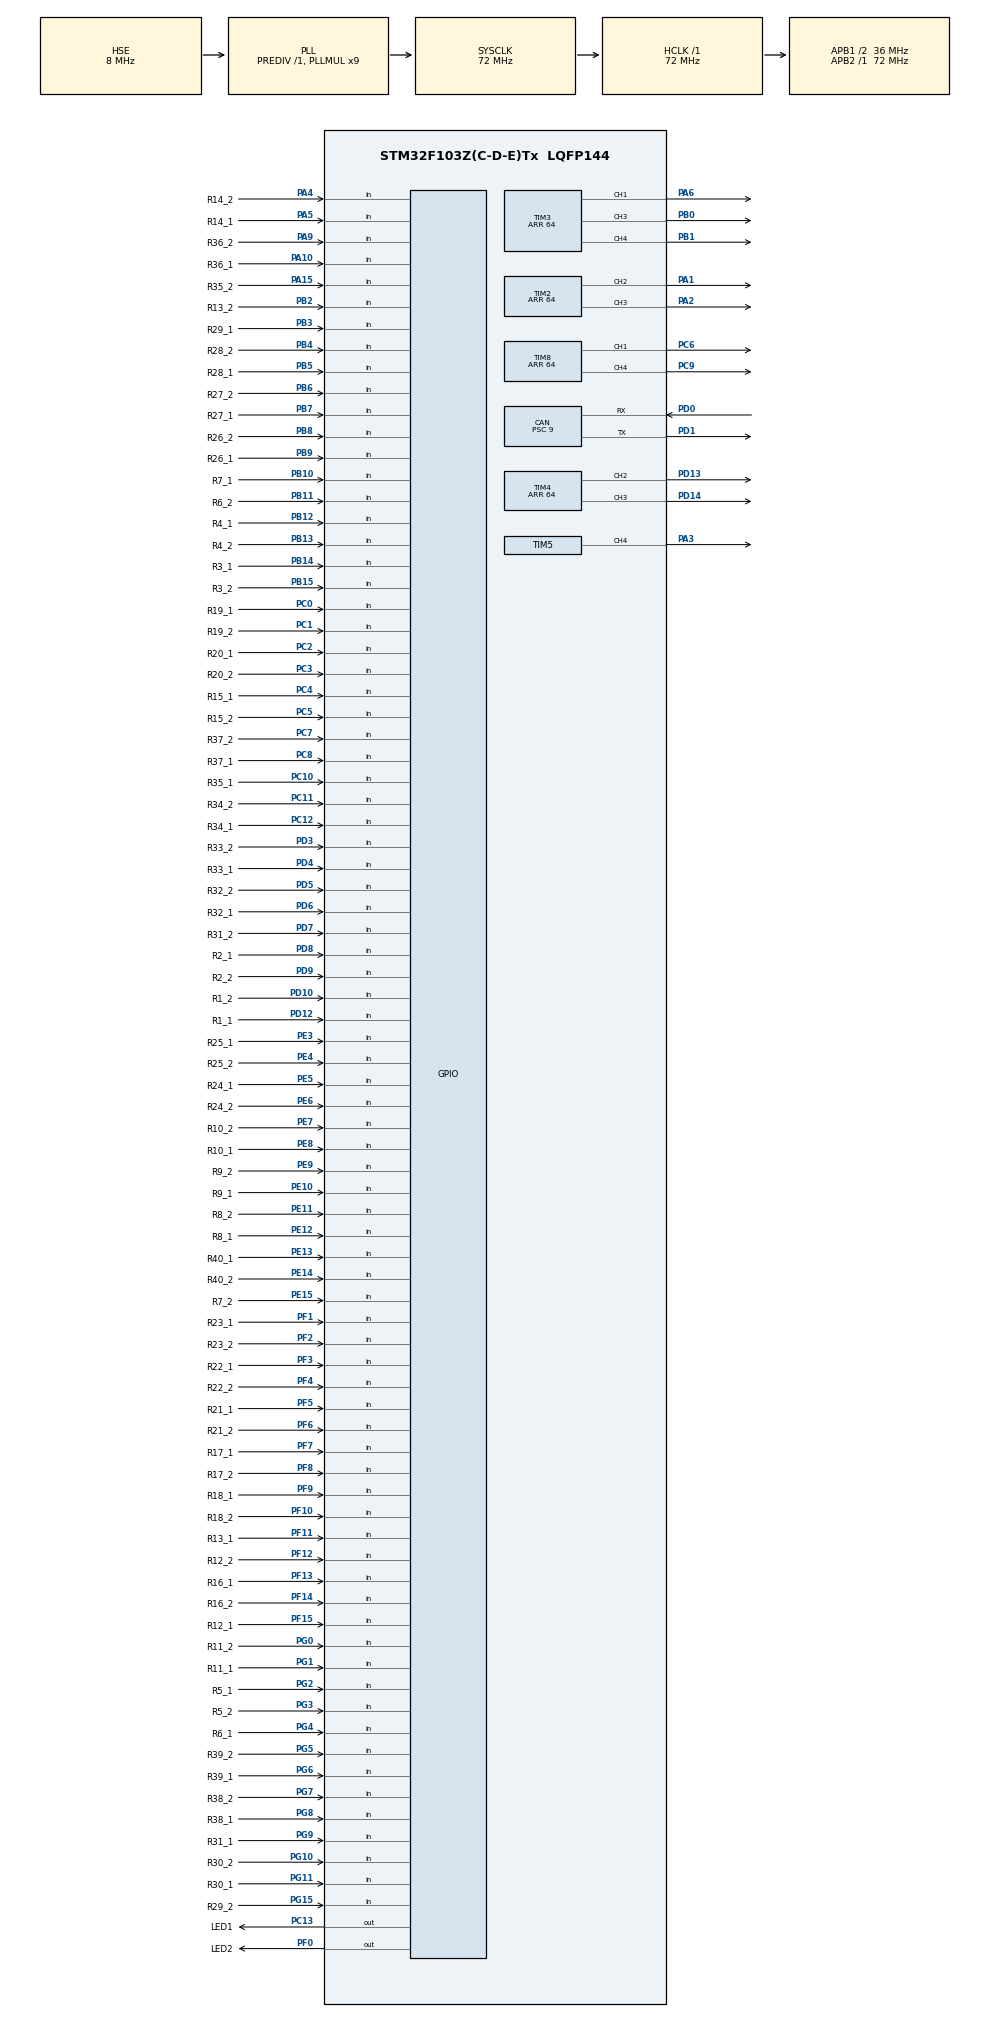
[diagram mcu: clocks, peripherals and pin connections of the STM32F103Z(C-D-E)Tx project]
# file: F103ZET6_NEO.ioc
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CAN.BS1=CAN_BS1_3TQ
CAN.BS2=CAN_BS2_4TQ
CAN.CalculateBaudRate=500000
CAN.CalculateTimeBit=2000
CAN.CalculateTimeQuantum=250.0
CAN.Prescaler=9
CAN.SJW=CAN_SJW_1TQ
Dma.Request0=TIM4_CH2
Dma.Request1=TIM4_CH3
Dma.Request2=TIM2_CH3
Dma.Request3=TIM2_CH2/CH4
Dma.Request4=TIM3_CH1/TRIG
Dma.Request5=TIM3_CH3
Dma.Request6=TIM3_CH4/UP
Dma.Request7=TIM5_CH4/TRIG
Dma.Request8=TIM8_CH4/TRIG/COM
Dma.Request9=TIM8_CH1
Dma.TIM2_CH2/CH4.3.Direction=DMA_MEMORY_TO_PERIPH
Dma.TIM2_CH2/CH4.3.Instance=DMA1_Channel7
Dma.TIM2_CH2/CH4.3.MemDataAlignment=DMA_MDATAALIGN_WORD
Dma.TIM2_CH2/CH4.3.MemInc=DMA_MINC_ENABLE
Dma.TIM2_CH2/CH4.3.Mode=DMA_NORMAL
Dma.TIM2_CH2/CH4.3.PeriphDataAlignment=DMA_PDATAALIGN_WORD
Dma.TIM2_CH2/CH4.3.PeriphInc=DMA_PINC_DISABLE
Dma.TIM2_CH2/CH4.3.Priority=DMA_PRIORITY_VERY_HIGH
Dma.TIM2_CH3.2.Direction=DMA_MEMORY_TO_PERIPH
Dma.TIM2_CH3.2.Instance=DMA1_Channel1
Dma.TIM2_CH3.2.MemDataAlignment=DMA_MDATAALIGN_WORD
Dma.TIM2_CH3.2.MemInc=DMA_MINC_ENABLE
Dma.TIM2_CH3.2.Mode=DMA_NORMAL
Dma.TIM2_CH3.2.PeriphDataAlignment=DMA_PDATAALIGN_WORD
Dma.TIM2_CH3.2.PeriphInc=DMA_PINC_DISABLE
Dma.TIM2_CH3.2.Priority=DMA_PRIORITY_VERY_HIGH
Dma.TIM3_CH1/TRIG.4.Direction=DMA_MEMORY_TO_PERIPH
Dma.TIM3_CH1/TRIG.4.Instance=DMA1_Channel6
Dma.TIM3_CH1/TRIG.4.MemDataAlignment=DMA_MDATAALIGN_WORD
Dma.TIM3_CH1/TRIG.4.MemInc=DMA_MINC_ENABLE
Dma.TIM3_CH1/TRIG.4.Mode=DMA_NORMAL
Dma.TIM3_CH1/TRIG.4.PeriphDataAlignment=DMA_PDATAALIGN_WORD
Dma.TIM3_CH1/TRIG.4.PeriphInc=DMA_PINC_DISABLE
Dma.TIM3_CH1/TRIG.4.Priority=DMA_PRIORITY_VERY_HIGH
Dma.TIM3_CH3.5.Direction=DMA_MEMORY_TO_PERIPH
Dma.TIM3_CH3.5.Instance=DMA1_Channel2
Dma.TIM3_CH3.5.MemDataAlignment=DMA_MDATAALIGN_WORD
Dma.TIM3_CH3.5.MemInc=DMA_MINC_ENABLE
Dma.TIM3_CH3.5.Mode=DMA_NORMAL
Dma.TIM3_CH3.5.PeriphDataAlignment=DMA_PDATAALIGN_WORD
Dma.TIM3_CH3.5.PeriphInc=DMA_PINC_DISABLE
Dma.TIM3_CH3.5.Priority=DMA_PRIORITY_VERY_HIGH
Dma.TIM3_CH4/UP.6.Direction=DMA_MEMORY_TO_PERIPH
Dma.TIM3_CH4/UP.6.Instance=DMA1_Channel3
Dma.TIM3_CH4/UP.6.MemDataAlignment=DMA_MDATAALIGN_WORD
Dma.TIM3_CH4/UP.6.MemInc=DMA_MINC_ENABLE
Dma.TIM3_CH4/UP.6.Mode=DMA_NORMAL
Dma.TIM3_CH4/UP.6.PeriphDataAlignment=DMA_PDATAALIGN_WORD
Dma.TIM3_CH4/UP.6.PeriphInc=DMA_PINC_DISABLE
Dma.TIM3_CH4/UP.6.Priority=DMA_PRIORITY_VERY_HIGH
Dma.TIM4_CH2.0.Direction=DMA_MEMORY_TO_PERIPH
Dma.TIM4_CH2.0.Instance=DMA1_Channel4
Dma.TIM4_CH2.0.MemDataAlignment=DMA_MDATAALIGN_WORD
Dma.TIM4_CH2.0.MemInc=DMA_MINC_ENABLE
Dma.TIM4_CH2.0.Mode=DMA_NORMAL
Dma.TIM4_CH2.0.PeriphDataAlignment=DMA_PDATAALIGN_WORD
Dma.TIM4_CH2.0.PeriphInc=DMA_PINC_DISABLE
Dma.TIM4_CH2.0.Priority=DMA_PRIORITY_VERY_HIGH
Dma.TIM4_CH3.1.Direction=DMA_MEMORY_TO_PERIPH
Dma.TIM4_CH3.1.Instance=DMA1_Channel5
Dma.TIM4_CH3.1.MemDataAlignment=DMA_MDATAALIGN_WORD
Dma.TIM4_CH3.1.MemInc=DMA_MINC_ENABLE
Dma.TIM4_CH3.1.Mode=DMA_NORMAL
Dma.TIM4_CH3.1.PeriphDataAlignment=DMA_PDATAALIGN_WORD
Dma.TIM4_CH3.1.PeriphInc=DMA_PINC_DISABLE
Dma.TIM4_CH3.1.Priority=DMA_PRIORITY_VERY_HIGH
Dma.TIM5_CH4/TRIG.7.Direction=DMA_MEMORY_TO_PERIPH
Dma.TIM5_CH4/TRIG.7.Instance=DMA2_Channel1
Dma.TIM5_CH4/TRIG.7.MemDataAlignment=DMA_MDATAALIGN_WORD
Dma.TIM5_CH4/TRIG.7.MemInc=DMA_MINC_ENABLE
Dma.TIM5_CH4/TRIG.7.Mode=DMA_NORMAL
Dma.TIM5_CH4/TRIG.7.PeriphDataAlignment=DMA_PDATAALIGN_WORD
Dma.TIM5_CH4/TRIG.7.PeriphInc=DMA_PINC_DISABLE
Dma.TIM5_CH4/TRIG.7.Priority=DMA_PRIORITY_VERY_HIGH
Dma.TIM8_CH1.9.Direction=DMA_MEMORY_TO_PERIPH
Dma.TIM8_CH1.9.Instance=DMA2_Channel3
Dma.TIM8_CH1.9.MemDataAlignment=DMA_MDATAALIGN_WORD
Dma.TIM8_CH1.9.MemInc=DMA_MINC_ENABLE
Dma.TIM8_CH1.9.Mode=DMA_NORMAL
Dma.TIM8_CH1.9.PeriphDataAlignment=DMA_PDATAALIGN_WORD
Dma.TIM8_CH1.9.PeriphInc=DMA_PINC_DISABLE
Dma.TIM8_CH1.9.Priority=DMA_PRIORITY_VERY_HIGH
Dma.TIM8_CH4/TRIG/COM.8.Direction=DMA_MEMORY_TO_PERIPH
Dma.TIM8_CH4/TRIG/COM.8.Instance=DMA2_Channel2
Dma.TIM8_CH4/TRIG/COM.8.MemDataAlignment=DMA_MDATAALIGN_WORD
Dma.TIM8_CH4/TRIG/COM.8.MemInc=DMA_MINC_ENABLE
Dma.TIM8_CH4/TRIG/COM.8.Mode=DMA_NORMAL
Dma.TIM8_CH4/TRIG/COM.8.PeriphDataAlignment=DMA_PDATAALIGN_WORD
Dma.TIM8_CH4/TRIG/COM.8.PeriphInc=DMA_PINC_DISABLE
Dma.TIM8_CH4/TRIG/COM.8.Priority=DMA_PRIORITY_VERY_HIGH
Mcu.Family=STM32F1
Mcu.Name=STM32F103Z(C-D-E)Tx
Mcu.Package=LQFP144
NVIC.DMA1_Channel1_IRQn=true\:0\:0\:false\:false\:true\:false\:true\:true
NVIC.DMA1_Channel2_IRQn=true\:0\:0\:false\:false\:true\:false\:true\:true
NVIC.DMA1_Channel3_IRQn=true\:0\:0\:false\:false\:true\:false\:true\:true
NVIC.DMA1_Channel4_IRQn=true\:0\:0\:false\:false\:true\:false\:true\:true
NVIC.DMA1_Channel5_IRQn=true\:0\:0\:false\:false\:true\:false\:true\:true
NVIC.DMA1_Channel6_IRQn=true\:0\:0\:false\:false\:true\:false\:true\:true
NVIC.DMA1_Channel7_IRQn=true\:0\:0\:false\:false\:true\:false\:true\:true
NVIC.DMA2_Channel1_IRQn=true\:0\:0\:false\:false\:true\:false\:true\:true
NVIC.DMA2_Channel2_IRQn=true\:0\:0\:false\:false\:true\:false\:true\:true
NVIC.DMA2_Channel3_IRQn=true\:0\:0\:false\:false\:true\:false\:true\:true
NVIC.PriorityGroup=NVIC_PRIORITYGROUP_4
NVIC.TIM7_IRQn=true\:0\:0\:false\:false\:true\:true\:true\:true
OSC_IN.Mode=HSE-External-Oscillator
OSC_IN.Signal=RCC_OSC_IN
OSC_OUT.Mode=HSE-External-Oscillator
OSC_OUT.Signal=RCC_OSC_OUT
PA1.Signal=S_TIM2_CH2
PA10.GPIO_Label=R36_1
PA10.GPIO_PuPd=GPIO_PULLUP
PA10.Signal=GPIO_Input
PA13.Mode=Serial_Wire
PA13.Signal=SYS_JTMS-SWDIO
PA14.Mode=Serial_Wire
PA14.Signal=SYS_JTCK-SWCLK
PA15.GPIO_Label=R35_2
PA15.GPIO_PuPd=GPIO_PULLUP
PA15.Signal=GPIO_Input
PA2.Signal=S_TIM2_CH3
PA3.Signal=S_TIM5_CH4
PA4.GPIO_Label=R14_2
PA4.GPIO_PuPd=GPIO_PULLUP
PA4.Signal=GPIO_Input
PA5.GPIO_Label=R14_1
PA5.GPIO_PuPd=GPIO_PULLUP
PA5.Signal=GPIO_Input
PA6.Signal=S_TIM3_CH1
PA9.GPIO_Label=R36_2
PA9.GPIO_PuPd=GPIO_PULLUP
PA9.Signal=GPIO_Input
PB0.Signal=S_TIM3_CH3
PB1.Signal=S_TIM3_CH4
PB10.GPIO_Label=R7_1
PB10.GPIO_PuPd=GPIO_PULLUP
PB10.Signal=GPIO_Input
PB11.GPIO_Label=R6_2
PB11.GPIO_PuPd=GPIO_PULLUP
PB11.Signal=GPIO_Input
PB12.GPIO_Label=R4_1
PB12.GPIO_PuPd=GPIO_PULLUP
PB12.Signal=GPIO_Input
PB13.GPIO_Label=R4_2
PB13.GPIO_PuPd=GPIO_PULLUP
PB13.Signal=GPIO_Input
PB14.GPIO_Label=R3_1
PB14.GPIO_PuPd=GPIO_PULLUP
PB14.Signal=GPIO_Input
PB15.GPIO_Label=R3_2
PB15.GPIO_PuPd=GPIO_PULLUP
PB15.Signal=GPIO_Input
PB2.GPIO_Label=R13_2
PB2.GPIO_PuPd=GPIO_PULLUP
PB2.Signal=GPIO_Input
PB3.GPIO_Label=R29_1
PB3.GPIO_PuPd=GPIO_PULLUP
PB3.Signal=GPIO_Input
PB4.GPIO_Label=R28_2
PB4.GPIO_PuPd=GPIO_PULLUP
PB4.Signal=GPIO_Input
PB5.GPIO_Label=R28_1
PB5.GPIO_PuPd=GPIO_PULLUP
PB5.Signal=GPIO_Input
PB6.GPIO_Label=R27_2
PB6.GPIO_PuPd=GPIO_PULLUP
PB6.Signal=GPIO_Input
PB7.GPIO_Label=R27_1
PB7.GPIO_PuPd=GPIO_PULLUP
PB7.Signal=GPIO_Input
PB8.GPIO_Label=R26_2
PB8.GPIO_PuPd=GPIO_PULLUP
PB8.Signal=GPIO_Input
PB9.GPIO_Label=R26_1
PB9.GPIO_PuPd=GPIO_PULLUP
PB9.Signal=GPIO_Input
PC0.GPIO_Label=R19_1
PC0.GPIO_PuPd=GPIO_PULLUP
PC0.Signal=GPIO_Input
PC1.GPIO_Label=R19_2
PC1.GPIO_PuPd=GPIO_PULLUP
PC1.Signal=GPIO_Input
PC10.GPIO_Label=R35_1
PC10.GPIO_PuPd=GPIO_PULLUP
PC10.Signal=GPIO_Input
PC11.GPIO_Label=R34_2
PC11.GPIO_PuPd=GPIO_PULLUP
PC11.Signal=GPIO_Input
PC12.GPIO_Label=R34_1
PC12.GPIO_PuPd=GPIO_PULLUP
PC12.Signal=GPIO_Input
PC13-TAMPER-RTC.GPIO_Label=LED1
PC13-TAMPER-RTC.Signal=GPIO_Output
PC2.GPIO_Label=R20_1
PC2.GPIO_PuPd=GPIO_PULLUP
PC2.Signal=GPIO_Input
PC3.GPIO_Label=R20_2
PC3.GPIO_PuPd=GPIO_PULLUP
PC3.Signal=GPIO_Input
PC4.GPIO_Label=R15_1
PC4.GPIO_PuPd=GPIO_PULLUP
PC4.Signal=GPIO_Input
PC5.GPIO_Label=R15_2
PC5.GPIO_PuPd=GPIO_PULLUP
PC5.Signal=GPIO_Input
PC6.Signal=S_TIM8_CH1
PC7.GPIO_Label=R37_2
PC7.GPIO_PuPd=GPIO_PULLUP
PC7.Signal=GPIO_Input
PC8.GPIO_Label=R37_1
PC8.GPIO_PuPd=GPIO_PULLUP
PC8.Signal=GPIO_Input
PC9.Signal=S_TIM8_CH4
PD0.Mode=CAN_Activate
PD0.Signal=CAN_RX
PD1.Mode=CAN_Activate
PD1.Signal=CAN_TX
PD10.GPIO_Label=R1_2
PD10.GPIO_PuPd=GPIO_PULLUP
PD10.Signal=GPIO_Input
PD12.GPIO_Label=R1_1
PD12.GPIO_PuPd=GPIO_PULLUP
PD12.Signal=GPIO_Input
PD13.Signal=S_TIM4_CH2
PD14.Signal=S_TIM4_CH3
PD3.GPIO_Label=R33_2
PD3.GPIO_PuPd=GPIO_PULLUP
PD3.Signal=GPIO_Input
PD4.GPIO_Label=R33_1
PD4.GPIO_PuPd=GPIO_PULLUP
PD4.Signal=GPIO_Input
PD5.GPIO_Label=R32_2
PD5.GPIO_PuPd=GPIO_PULLUP
PD5.Signal=GPIO_Input
PD6.GPIO_Label=R32_1
PD6.GPIO_PuPd=GPIO_PULLUP
PD6.Signal=GPIO_Input
PD7.GPIO_Label=R31_2
PD7.GPIO_PuPd=GPIO_PULLUP
PD7.Signal=GPIO_Input
PD8.GPIO_Label=R2_1
PD8.GPIO_PuPd=GPIO_PULLUP
PD8.Signal=GPIO_Input
PD9.GPIO_Label=R2_2
PD9.GPIO_PuPd=GPIO_PULLUP
PD9.Signal=GPIO_Input
PE10.GPIO_Label=R9_1
PE10.GPIO_PuPd=GPIO_PULLUP
PE10.Signal=GPIO_Input
PE11.GPIO_Label=R8_2
PE11.GPIO_PuPd=GPIO_PULLUP
PE11.Signal=GPIO_Input
PE12.GPIO_Label=R8_1
PE12.GPIO_PuPd=GPIO_PULLUP
PE12.Signal=GPIO_Input
PE13.GPIO_Label=R40_1
PE13.GPIO_PuPd=GPIO_PULLUP
PE13.Signal=GPIO_Input
PE14.GPIO_Label=R40_2
PE14.GPIO_PuPd=GPIO_PULLUP
PE14.Signal=GPIO_Input
PE15.GPIO_Label=R7_2
PE15.GPIO_PuPd=GPIO_PULLUP
PE15.Signal=GPIO_Input
PE3.GPIO_Label=R25_1
PE3.GPIO_PuPd=GPIO_PULLUP
PE3.Signal=GPIO_Input
PE4.GPIO_Label=R25_2
PE4.GPIO_PuPd=GPIO_PULLUP
PE4.Signal=GPIO_Input
PE5.GPIO_Label=R24_1
PE5.GPIO_PuPd=GPIO_PULLUP
PE5.Signal=GPIO_Input
PE6.GPIO_Label=R24_2
PE6.GPIO_PuPd=GPIO_PULLUP
PE6.Signal=GPIO_Input
PE7.GPIO_Label=R10_2
PE7.GPIO_PuPd=GPIO_PULLUP
PE7.Signal=GPIO_Input
PE8.GPIO_Label=R10_1
PE8.GPIO_PuPd=GPIO_PULLUP
PE8.Signal=GPIO_Input
PE9.GPIO_Label=R9_2
PE9.GPIO_PuPd=GPIO_PULLUP
PE9.Signal=GPIO_Input
PF0.GPIO_Label=LED2
PF0.Signal=GPIO_Output
PF1.GPIO_Label=R23_1
PF1.GPIO_PuPd=GPIO_PULLUP
PF1.Signal=GPIO_Input
PF10.GPIO_Label=R18_2
PF10.GPIO_PuPd=GPIO_PULLUP
PF10.Signal=GPIO_Input
PF11.GPIO_Label=R13_1
PF11.GPIO_PuPd=GPIO_PULLUP
PF11.Signal=GPIO_Input
PF12.GPIO_Label=R12_2
PF12.GPIO_PuPd=GPIO_PULLUP
PF12.Signal=GPIO_Input
PF13.GPIO_Label=R16_1
PF13.GPIO_PuPd=GPIO_PULLUP
PF13.Signal=GPIO_Input
PF14.GPIO_Label=R16_2
PF14.GPIO_PuPd=GPIO_PULLUP
PF14.Signal=GPIO_Input
PF15.GPIO_Label=R12_1
PF15.GPIO_PuPd=GPIO_PULLUP
PF15.Signal=GPIO_Input
PF2.GPIO_Label=R23_2
PF2.GPIO_PuPd=GPIO_PULLUP
PF2.Signal=GPIO_Input
PF3.GPIO_Label=R22_1
PF3.GPIO_PuPd=GPIO_PULLUP
PF3.Signal=GPIO_Input
PF4.GPIO_Label=R22_2
PF4.GPIO_PuPd=GPIO_PULLUP
PF4.Signal=GPIO_Input
PF5.GPIO_Label=R21_1
PF5.GPIO_PuPd=GPIO_PULLUP
PF5.Signal=GPIO_Input
PF6.GPIO_Label=R21_2
PF6.GPIO_PuPd=GPIO_PULLUP
PF6.Signal=GPIO_Input
PF7.GPIO_Label=R17_1
PF7.GPIO_PuPd=GPIO_PULLUP
PF7.Signal=GPIO_Input
PF8.GPIO_Label=R17_2
PF8.GPIO_PuPd=GPIO_PULLUP
PF8.Signal=GPIO_Input
PF9.GPIO_Label=R18_1
PF9.GPIO_PuPd=GPIO_PULLUP
PF9.Signal=GPIO_Input
PG0.GPIO_Label=R11_2
PG0.GPIO_PuPd=GPIO_PULLUP
PG0.Signal=GPIO_Input
PG1.GPIO_Label=R11_1
PG1.GPIO_PuPd=GPIO_PULLUP
PG1.Signal=GPIO_Input
PG10.GPIO_Label=R30_2
PG10.GPIO_PuPd=GPIO_PULLUP
PG10.Signal=GPIO_Input
PG11.GPIO_Label=R30_1
PG11.GPIO_PuPd=GPIO_PULLUP
PG11.Signal=GPIO_Input
PG15.GPIO_Label=R29_2
PG15.GPIO_PuPd=GPIO_PULLUP
PG15.Signal=GPIO_Input
PG2.GPIO_Label=R5_1
PG2.GPIO_PuPd=GPIO_PULLUP
PG2.Signal=GPIO_Input
PG3.GPIO_Label=R5_2
PG3.GPIO_PuPd=GPIO_PULLUP
PG3.Signal=GPIO_Input
PG4.GPIO_Label=R6_1
PG4.GPIO_PuPd=GPIO_PULLUP
PG4.Signal=GPIO_Input
PG5.GPIO_Label=R39_2
PG5.GPIO_PuPd=GPIO_PULLUP
PG5.Signal=GPIO_Input
PG6.GPIO_Label=R39_1
PG6.GPIO_PuPd=GPIO_PULLUP
PG6.Signal=GPIO_Input
PG7.GPIO_Label=R38_2
PG7.GPIO_PuPd=GPIO_PULLUP
PG7.Signal=GPIO_Input
PG8.GPIO_Label=R38_1
PG8.GPIO_PuPd=GPIO_PULLUP
PG8.Signal=GPIO_Input
PG9.GPIO_Label=R31_1
PG9.GPIO_PuPd=GPIO_PULLUP
PG9.Signal=GPIO_Input
ProjectManager.HeapSize=0x200
ProjectManager.StackSize=0x400
ProjectManager.TargetToolchain=STM32CubeIDE
RCC.AHBFreq_Value=72000000
RCC.APB1CLKDivider=RCC_HCLK_DIV2
RCC.APB1Freq_Value=36000000
RCC.APB1TimFreq_Value=72000000
RCC.APB2Freq_Value=72000000
RCC.APB2TimFreq_Value=72000000
RCC.HCLKFreq_Value=72000000
RCC.PLLMUL=RCC_PLL_MUL9
RCC.PLLSourceVirtual=RCC_PLLSOURCE_HSE
RCC.SYSCLKFreq_VALUE=72000000
RCC.SYSCLKSource=RCC_SYSCLKSOURCE_PLLCLK
RCC.USBFreq_Value=72000000
SH.S_TIM2_CH2.0=TIM2_CH2,PWM Generation2 CH2
SH.S_TIM2_CH3.0=TIM2_CH3,PWM Generation3 CH3
SH.S_TIM3_CH1.0=TIM3_CH1,PWM Generation1 CH1
SH.S_TIM3_CH3.0=TIM3_CH3,PWM Generation3 CH3
SH.S_TIM3_CH4.0=TIM3_CH4,PWM Generation4 CH4
SH.S_TIM4_CH2.0=TIM4_CH2,PWM Generation2 CH2
SH.S_TIM4_CH3.0=TIM4_CH3,PWM Generation3 CH3
SH.S_TIM5_CH4.0=TIM5_CH4,PWM Generation4 CH4
SH.S_TIM8_CH1.0=TIM8_CH1,PWM Generation1 CH1
SH.S_TIM8_CH4.0=TIM8_CH4,PWM Generation4 CH4
TIM2.Channel-PWM\ Generation2\ CH2=TIM_CHANNEL_2
TIM2.Channel-PWM\ Generation3\ CH3=TIM_CHANNEL_3
TIM2.Period=64
TIM3.Channel-PWM\ Generation1\ CH1=TIM_CHANNEL_1
TIM3.Channel-PWM\ Generation3\ CH3=TIM_CHANNEL_3
TIM3.Channel-PWM\ Generation4\ CH4=TIM_CHANNEL_4
TIM3.Period=64
TIM4.AutoReloadPreload=TIM_AUTORELOAD_PRELOAD_DISABLE
TIM4.Channel-PWM\ Generation2\ CH2=TIM_CHANNEL_2
TIM4.Channel-PWM\ Generation3\ CH3=TIM_CHANNEL_3
TIM4.Period=64
TIM5.Channel-PWM\ Generation4\ CH4=TIM_CHANNEL_4
TIM5.Period=64
TIM7.AutoReloadPreload=TIM_AUTORELOAD_PRELOAD_DISABLE
TIM7.Period=10-1
TIM7.Prescaler=7200-1
TIM8.Channel-PWM\ Generation1\ CH1=TIM_CHANNEL_1
TIM8.Channel-PWM\ Generation4\ CH4=TIM_CHANNEL_4
TIM8.Period=64
VP_TIM4_VS_ClockSourceINT.Mode=Internal
VP_TIM7_VS_ClockSourceINT.Mode=Enable_Timer
board=custom

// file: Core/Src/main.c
/* USER CODE BEGIN Header */
/**
  ******************************************************************************
  * @file           : main.c
  * @brief          : Main program body
  ******************************************************************************
  * @attention
  *
  * Copyright (c) 2024 STMicroelectronics.
  * All rights reserved.
  *
  * This software is licensed under terms that can be found in the LICENSE file
  * in the root directory of this software component.
  * If no LICENSE file comes with this software, it is provided AS-IS.
  *
  ******************************************************************************
  */
/* USER CODE END Header */
#include "main.h"
#include "can.h"
#include "dma.h"
#include "tim.h"
#include "gpio.h"

/* USER CODE BEGIN Includes */

#include "rotary.h"
#include "LED.h"

/* USER CODE END Includes */

/* USER CODE BEGIN PD */

#define ROTARY_COUNT 40

/* USER CODE END PD */

/* USER CODE BEGIN PV */

RotaryEnc_t rotary[ROTARY_COUNT];
Module_t modules[MODULE_COUNT];

CAN_TxHeaderTypeDef   TxHeader;
uint8_t               TxData[8];
uint32_t              TxMailbox;

/* USER CODE END PV */

void SystemClock_Config(void);
/* USER CODE BEGIN PFP */

void InitRotary(uint8_t arrNr, GPIO_TypeDef *GPIO_port1, uint16_t GPIO_Pin1, GPIO_TypeDef *GPIO_port2, uint16_t GPIO_Pin2);

/* USER CODE END PFP */

/* USER CODE BEGIN 0 */

void HAL_TIM_PWM_PulseFinishedCallback(TIM_HandleTypeDef *htim)
{
	for(uint8_t i = 0; i < MODULE_COUNT; i++)
	{
		if (modules[i].status==MODULE_STATUS_UPDATING)
		{
			HAL_TIM_PWM_Stop_DMA(modules[i].htim, modules[i].Channel);
			modules[i].status = MODULE_STATUS_OK;
			break;
		}
	}
}

// Callback: timer has rolled over
void HAL_TIM_PeriodElapsedCallback(TIM_HandleTypeDef *htim)
{
  // Check which version of the timer triggered this callback and toggle LED
  if (htim == &htim7 )
  {
	  //HAL_GPIO_TogglePin(LED_GPIO_Port, LED_Pin);

	  for(int r=0; r < ROTARY_COUNT; r++)
	  {
		  if(HAL_GPIO_ReadPin(rotary[r].pin1.GPIO_port, rotary[r].pin1.GPIO_Pin)==GPIO_PIN_SET)
		  {
			  rotary[r].pinStatus.status.r1 = 1;
		  } else {
			  rotary[r].pinStatus.status.r1 = 0;
		  }
		  if(HAL_GPIO_ReadPin(rotary[r].pin2.GPIO_port, rotary[r].pin2.GPIO_Pin)==GPIO_PIN_SET)
		  {
			  rotary[r].pinStatus.status.r2 = 1;
		  } else {
			  rotary[r].pinStatus.status.r2 = 0;
		  }

		  if ( rotary[r].pinStatus.data != rotary[r].historyStatus.data ) {
			  RotaryProcess(&rotary[r], COLOR_COUNT-1);
		  }
	  };
  }
}

/* USER CODE END 0 */

int main(void)
{
  /* USER CODE BEGIN 1 */

	  int i, j, k;
	  uint16_t stepSize;

  /* USER CODE END 1 */

  /* MCU Configuration--------------------------------------------------------*/

  /* Reset of all peripherals, Initializes the Flash interface and the Systick. */
  HAL_Init();

  /* USER CODE BEGIN Init */

  InitRotary(0, R1_1_GPIO_Port, R1_1_Pin, R1_2_GPIO_Port, R1_2_Pin);
  InitRotary(1, R2_1_GPIO_Port, R2_1_Pin, R2_2_GPIO_Port, R2_2_Pin);
  InitRotary(2, R3_1_GPIO_Port, R3_1_Pin, R3_2_GPIO_Port, R3_2_Pin);
  InitRotary(3, R4_1_GPIO_Port, R4_1_Pin, R4_2_GPIO_Port, R4_2_Pin);
  InitRotary(4, R5_1_GPIO_Port, R5_1_Pin, R5_2_GPIO_Port, R5_2_Pin);
  InitRotary(5, R6_1_GPIO_Port, R6_1_Pin, R6_2_GPIO_Port, R6_2_Pin);
  InitRotary(6, R7_1_GPIO_Port, R7_1_Pin, R7_2_GPIO_Port, R7_2_Pin);
  InitRotary(7, R8_1_GPIO_Port, R8_1_Pin, R8_2_GPIO_Port, R8_2_Pin);
  InitRotary(8, R9_1_GPIO_Port, R9_1_Pin, R9_2_GPIO_Port, R9_2_Pin);
  InitRotary(9, R10_1_GPIO_Port, R10_1_Pin, R10_2_GPIO_Port, R10_2_Pin);
  InitRotary(10, R11_1_GPIO_Port, R11_1_Pin, R11_2_GPIO_Port, R11_2_Pin);
  InitRotary(11, R12_1_GPIO_Port, R12_1_Pin, R12_2_GPIO_Port, R12_2_Pin);
  InitRotary(12, R13_1_GPIO_Port, R13_1_Pin, R13_2_GPIO_Port, R13_2_Pin);
  InitRotary(13, R14_1_GPIO_Port, R14_1_Pin, R14_2_GPIO_Port, R14_2_Pin);
  InitRotary(14, R15_1_GPIO_Port, R15_1_Pin, R15_2_GPIO_Port, R15_2_Pin);
  InitRotary(15, R16_1_GPIO_Port, R16_1_Pin, R16_2_GPIO_Port, R16_2_Pin);
  InitRotary(16, R17_1_GPIO_Port, R17_1_Pin, R17_2_GPIO_Port, R17_2_Pin);
  InitRotary(17, R18_1_GPIO_Port, R18_1_Pin, R18_2_GPIO_Port, R18_2_Pin);
  InitRotary(18, R19_1_GPIO_Port, R19_1_Pin, R19_2_GPIO_Port, R19_2_Pin);
  InitRotary(19, R20_1_GPIO_Port, R20_1_Pin, R20_2_GPIO_Port, R20_2_Pin);
  InitRotary(20, R21_1_GPIO_Port, R21_1_Pin, R21_2_GPIO_Port, R21_2_Pin);
  InitRotary(21, R22_1_GPIO_Port, R22_1_Pin, R22_2_GPIO_Port, R22_2_Pin);
  InitRotary(22, R23_1_GPIO_Port, R23_1_Pin, R23_2_GPIO_Port, R23_2_Pin);
  InitRotary(23, R24_1_GPIO_Port, R24_1_Pin, R24_2_GPIO_Port, R24_2_Pin);
  InitRotary(24, R25_1_GPIO_Port, R25_1_Pin, R25_2_GPIO_Port, R25_2_Pin);
  InitRotary(25, R26_1_GPIO_Port, R26_1_Pin, R26_2_GPIO_Port, R26_2_Pin);
  InitRotary(26, R27_1_GPIO_Port, R27_1_Pin, R27_2_GPIO_Port, R27_2_Pin);
  InitRotary(27, R28_1_GPIO_Port, R28_1_Pin, R28_2_GPIO_Port, R28_2_Pin);
  InitRotary(28, R29_1_GPIO_Port, R29_1_Pin, R29_2_GPIO_Port, R29_2_Pin);
  InitRotary(29, R30_1_GPIO_Port, R30_1_Pin, R30_2_GPIO_Port, R30_2_Pin);
  InitRotary(30, R31_1_GPIO_Port, R31_1_Pin, R31_2_GPIO_Port, R31_2_Pin);
  InitRotary(31, R32_1_GPIO_Port, R32_1_Pin, R32_2_GPIO_Port, R32_2_Pin);
  InitRotary(32, R33_1_GPIO_Port, R33_1_Pin, R33_2_GPIO_Port, R33_2_Pin);
  InitRotary(33, R34_1_GPIO_Port, R34_1_Pin, R34_2_GPIO_Port, R34_2_Pin);
  InitRotary(34, R35_1_GPIO_Port, R35_1_Pin, R35_2_GPIO_Port, R35_2_Pin);
  InitRotary(35, R36_1_GPIO_Port, R36_1_Pin, R36_2_GPIO_Port, R36_2_Pin);
  InitRotary(36, R37_1_GPIO_Port, R37_1_Pin, R37_2_GPIO_Port, R37_2_Pin);
  InitRotary(37, R38_1_GPIO_Port, R38_1_Pin, R38_2_GPIO_Port, R38_2_Pin);
  InitRotary(38, R39_1_GPIO_Port, R39_1_Pin, R39_2_GPIO_Port, R39_2_Pin);
  InitRotary(39, R40_1_GPIO_Port, R40_1_Pin, R40_2_GPIO_Port, R40_2_Pin);

  /* USER CODE END Init */

  /* Configure the system clock */
  SystemClock_Config();

  /* Initialize all configured peripherals */
  MX_GPIO_Init();
  MX_DMA_Init();
  MX_TIM4_Init();
  MX_TIM7_Init();
  MX_CAN_Init();
  MX_TIM2_Init();
  MX_TIM3_Init();
  MX_TIM5_Init();
  MX_TIM8_Init();
  /* USER CODE BEGIN 2 */

  InitModule(&modules[0], &htim4, TIM_CHANNEL_2);
  InitModule(&modules[1], &htim2, TIM_CHANNEL_3);
  InitModule(&modules[2], &htim2, TIM_CHANNEL_2);
  InitModule(&modules[3], &htim3, TIM_CHANNEL_1);
  InitModule(&modules[4], &htim3, TIM_CHANNEL_3);
  InitModule(&modules[5], &htim3, TIM_CHANNEL_4);
  InitModule(&modules[6], &htim4, TIM_CHANNEL_3);
  InitModule(&modules[7], &htim5, TIM_CHANNEL_4);
  InitModule(&modules[8], &htim8, TIM_CHANNEL_4);
  InitModule(&modules[9], &htim8, TIM_CHANNEL_1);

  // Start timer
  HAL_TIM_Base_Start_IT(&htim7);

  //Can
  HAL_CAN_Start(&hcan);

  TxHeader.IDE = CAN_ID_STD;
  TxHeader.StdId = 0x446;
  TxHeader.RTR = CAN_RTR_DATA;
  TxHeader.DLC = 2;

  TxData[0] = 50;
  TxData[1] = 0xAA;

  /* USER CODE END 2 */

  /* Infinite loop */
  /* USER CODE BEGIN WHILE */
  k = 255;
  stepSize = 0;
  j=0;

  HAL_GPIO_WritePin(LED1_GPIO_Port, LED1_Pin, GPIO_PIN_SET);
  while (1)
  {
	  if(k==0)
	  {
		  k=100;
		  HAL_GPIO_TogglePin(LED2_GPIO_Port, LED2_Pin);
	  }
	  k--;//*/

	  for (int m=0; m < MODULE_COUNT; m++)
	  {
		  int changed = 0;
		  for(int r=0; r < 4; r++)
		  {
			  if(rotary[m*4 + r].changed){
				  SetPixelColorP(&modules[m].pixels[r], rotary[m*4 + r].counter % COLOR_COUNT);
				  changed = 1;
				  rotary[m*4 + r].changed=0;
			  }
		  }
		  if (changed) UpdateModule(&modules[m]);
	  }

	  for(uint8_t i = 0; i < MODULE_COUNT; i++)
	  {
		  if(modules[i].status == MODULE_STATUS_NEEDS_UPDATE)
		  {
			  UpdateModuleColor(&modules[i]);
			  //UpdateModule(&modules[i]);
			  break;
		  }
	  }
	  //if (HAL_CAN_AddTxMessage(&hcan, &TxHeader, TxData, &TxMailbox) != HAL_OK)
	  //{
	  //   Error_Handler ();
	  //}
	  //HAL_Delay(500);

    /* USER CODE END WHILE */

    /* USER CODE BEGIN 3 */
	  HAL_Delay(1);
  }
  /* USER CODE END 3 */
}

void SystemClock_Config(void)
{
  RCC_OscInitTypeDef RCC_OscInitStruct = {0};
  RCC_ClkInitTypeDef RCC_ClkInitStruct = {0};

  /** Initializes the RCC Oscillators according to the specified parameters
  * in the RCC_OscInitTypeDef structure.
  */
  RCC_OscInitStruct.OscillatorType = RCC_OSCILLATORTYPE_HSE;
  RCC_OscInitStruct.HSEState = RCC_HSE_ON;
  RCC_OscInitStruct.HSEPredivValue = RCC_HSE_PREDIV_DIV1;
  RCC_OscInitStruct.HSIState = RCC_HSI_ON;
  RCC_OscInitStruct.PLL.PLLState = RCC_PLL_ON;
  RCC_OscInitStruct.PLL.PLLSource = RCC_PLLSOURCE_HSE;
  RCC_OscInitStruct.PLL.PLLMUL = RCC_PLL_MUL9;
  if (HAL_RCC_OscConfig(&RCC_OscInitStruct) != HAL_OK)
  {
    Error_Handler();
  }

  /** Initializes the CPU, AHB and APB buses clocks
  */
  RCC_ClkInitStruct.ClockType = RCC_CLOCKTYPE_HCLK|RCC_CLOCKTYPE_SYSCLK
                              |RCC_CLOCKTYPE_PCLK1|RCC_CLOCKTYPE_PCLK2;
  RCC_ClkInitStruct.SYSCLKSource = RCC_SYSCLKSOURCE_PLLCLK;
  RCC_ClkInitStruct.AHBCLKDivider = RCC_SYSCLK_DIV1;
  RCC_ClkInitStruct.APB1CLKDivider = RCC_HCLK_DIV2;
  RCC_ClkInitStruct.APB2CLKDivider = RCC_HCLK_DIV1;

  if (HAL_RCC_ClockConfig(&RCC_ClkInitStruct, FLASH_LATENCY_2) != HAL_OK)
  {
    Error_Handler();
  }
}

/* USER CODE BEGIN 4 */

void InitRotary(uint8_t arrNr, GPIO_TypeDef *GPIO_port1, uint16_t GPIO_Pin1, GPIO_TypeDef *GPIO_port2, uint16_t GPIO_Pin2)
{
	  rotary[arrNr].pin1.GPIO_port=GPIO_port1;
	  rotary[arrNr].pin1.GPIO_Pin=GPIO_Pin1;
	  rotary[arrNr].pin2.GPIO_port=GPIO_port2;
	  rotary[arrNr].pin2.GPIO_Pin=GPIO_Pin2;
}

/* USER CODE END 4 */

void Error_Handler(void)
{
  __disable_irq();
  while (1)
  {
  }
}
